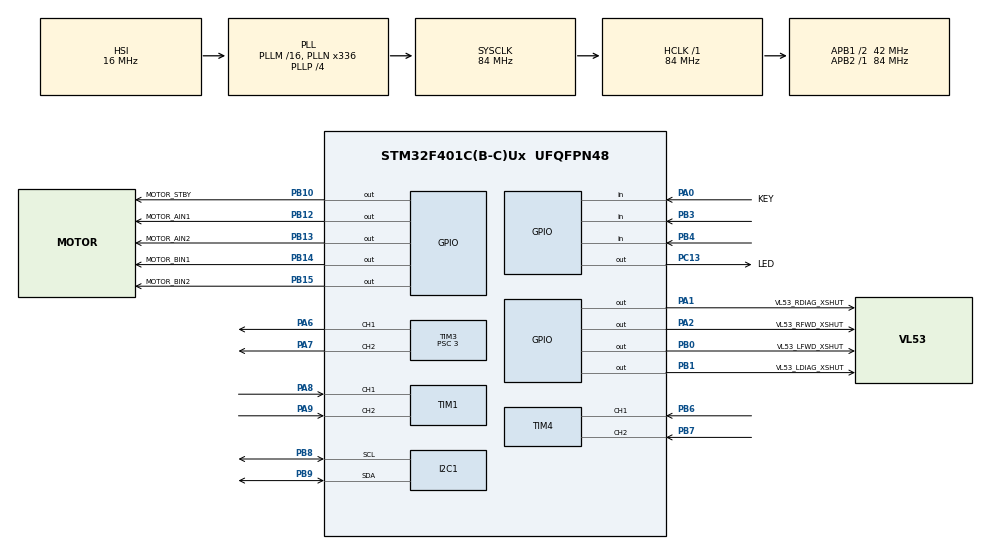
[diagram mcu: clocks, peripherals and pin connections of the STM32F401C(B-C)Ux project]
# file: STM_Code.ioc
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I2C1.I2C_Mode=I2C_Fast
Mcu.Family=STM32F4
Mcu.Name=STM32F401C(B-C)Ux
Mcu.Package=UFQFPN48
NVIC.PriorityGroup=NVIC_PRIORITYGROUP_4
PA0-WKUP.GPIO_Label=KEY
PA0-WKUP.GPIO_PuPd=GPIO_PULLUP
PA0-WKUP.Signal=GPIO_Input
PA1.GPIO_Label=VL53_RDIAG_XSHUT
PA1.GPIO_PuPd=GPIO_NOPULL
PA1.GPIO_Speed=GPIO_SPEED_FREQ_LOW
PA1.Signal=GPIO_Output
PA2.GPIO_Label=VL53_RFWD_XSHUT
PA2.GPIO_PuPd=GPIO_NOPULL
PA2.GPIO_Speed=GPIO_SPEED_FREQ_LOW
PA2.Signal=GPIO_Output
PB0.GPIO_Label=VL53_LFWD_XSHUT
PB0.GPIO_PuPd=GPIO_NOPULL
PB0.GPIO_Speed=GPIO_SPEED_FREQ_LOW
PB0.Signal=GPIO_Output
PB1.GPIO_Label=VL53_LDIAG_XSHUT
PB1.GPIO_PuPd=GPIO_NOPULL
PB1.GPIO_Speed=GPIO_SPEED_FREQ_LOW
PB1.Signal=GPIO_Output
PA13.Mode=Serial_Wire
PA13.Signal=SYS_JTMS-SWDIO
PA14.Mode=Serial_Wire
PA14.Signal=SYS_JTCK-SWCLK
PA6.Signal=S_TIM3_CH1
PA7.Signal=S_TIM3_CH2
PA8.Signal=S_TIM1_CH1
PA9.Signal=S_TIM1_CH2
PB10.GPIO_Label=MOTOR_STBY
PB10.Signal=GPIO_Output
PB12.GPIO_Label=MOTOR_AIN1
PB12.Signal=GPIO_Output
PB13.GPIO_Label=MOTOR_AIN2
PB13.Signal=GPIO_Output
PB14.GPIO_Label=MOTOR_BIN1
PB14.Signal=GPIO_Output
PB15.GPIO_Label=MOTOR_BIN2
PB15.Signal=GPIO_Output
PB3.GPIO_PuPd=GPIO_PULLUP
PB3.Signal=GPIO_Input
PB4.GPIO_PuPd=GPIO_PULLUP
PB4.Signal=GPIO_Input
PB6.Signal=S_TIM4_CH1
PB7.Signal=S_TIM4_CH2
PB8.Mode=I2C
PB8.Signal=I2C1_SCL
PB9.Mode=I2C
PB9.Signal=I2C1_SDA
PC13-ANTI_TAMP.GPIO_Label=LED
PC13-ANTI_TAMP.GPIO_PuPd=GPIO_NOPULL
PC13-ANTI_TAMP.PinState=GPIO_PIN_SET
PC13-ANTI_TAMP.Signal=GPIO_Output
ProjectManager.HeapSize=0x200
ProjectManager.StackSize=0x400
ProjectManager.TargetToolchain=STM32CubeIDE
RCC.48MHZClocksFreq_Value=84000000
RCC.AHBFreq_Value=84000000
RCC.APB1CLKDivider=RCC_HCLK_DIV2
RCC.APB1Freq_Value=42000000
RCC.APB1TimFreq_Value=84000000
RCC.APB2Freq_Value=84000000
RCC.APB2TimFreq_Value=84000000
RCC.CortexFreq_Value=84000000
RCC.HCLKFreq_Value=84000000
RCC.HSE_VALUE=25000000
RCC.HSI_VALUE=16000000
RCC.LSE_VALUE=32768
RCC.PLLN=336
RCC.PLLP=RCC_PLLP_DIV4
RCC.SYSCLKFreq_VALUE=84000000
RCC.SYSCLKSource=RCC_SYSCLKSOURCE_PLLCLK
RCC.VCOOutputFreq_Value=336000000
SH.S_TIM1_CH1.0=TIM1_CH1,Encoder_Interface
SH.S_TIM1_CH2.0=TIM1_CH2,Encoder_Interface
SH.S_TIM3_CH1.0=TIM3_CH1,PWM Generation1 CH1
SH.S_TIM3_CH2.0=TIM3_CH2,PWM Generation2 CH2
SH.S_TIM4_CH1.0=TIM4_CH1,Encoder_Interface
SH.S_TIM4_CH2.0=TIM4_CH2,Encoder_Interface
TIM1.EncoderMode=TIM_ENCODERMODE_TI12
TIM1.IC1Filter=4
TIM1.IC2Filter=4
TIM3.Channel-PWM\ Generation1\ CH1=TIM_CHANNEL_1
TIM3.Channel-PWM\ Generation2\ CH2=TIM_CHANNEL_2
TIM3.AutoReloadPreload=TIM_AUTORELOAD_PRELOAD_DISABLE
TIM3.ClockDivision=TIM_CLOCKDIVISION_DIV1
TIM3.CounterMode=TIM_COUNTERMODE_UP
TIM3.Period=999
TIM3.Prescaler=3
TIM4.EncoderMode=TIM_ENCODERMODE_TI12
TIM4.IC1Filter=4
TIM4.IC2Filter=4
VP_TIM3_VS_ClockSourceINT.Mode=Internal
board=custom

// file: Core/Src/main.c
/* USER CODE BEGIN Header */
/**
  ******************************************************************************
  * @file           : main.c
  * @brief          : Main program body
  ******************************************************************************
  * @attention
  *
  * Copyright (c) 2026 STMicroelectronics.
  * All rights reserved.
  *
  * This software is licensed under terms that can be found in the LICENSE file
  * in the root directory of this software component.
  * If no LICENSE file comes with this software, it is provided AS-IS.
  *
  ******************************************************************************
  */
/* USER CODE END Header */
#include "main.h"
#include "hardware_test.h"
#include "motor.h"
#include "motion.h"
#include "encoder.h"
#include "speed_control.h"
#include "tof_sensors.h"
#include "wall_detection.h"
#include "oled.h"

I2C_HandleTypeDef hi2c1;

TIM_HandleTypeDef htim1;
TIM_HandleTypeDef htim3;
TIM_HandleTypeDef htim4;

void SystemClock_Config(void);
static void MX_GPIO_Init(void);
static void MX_I2C1_Init(void);
static void MX_TIM1_Init(void);
static void MX_TIM3_Init(void);
static void MX_TIM4_Init(void);

int main(void)
{

  /* MCU Configuration--------------------------------------------------------*/

  /* Reset of all peripherals, Initializes the Flash interface and the Systick. */
  HAL_Init();

  /* Configure the system clock */
  SystemClock_Config();

  /* Initialize all configured peripherals */
  MX_GPIO_Init();
  MX_I2C1_Init();
  MX_TIM1_Init();
  MX_TIM3_Init();
  MX_TIM4_Init();
  /* USER CODE BEGIN 2 */

  /* Initialize motor PWM, but keep TB6612 STBY low until motion is requested. */
  motor_init();

  /*
   * Hardware verification mode.
   *
   * CubeMX owns all peripheral initialization above. The diagnostic layer
   * only consumes the initialized GPIO, I2C1, TIM1 and TIM4 peripherals.
   */
  encoder_init();
  speed_control_init();
  motion_init();
  wall_detection_init();
  hardware_test_init();
  if (!tof_sensors_init()) {
    oled_show_message("TOF ERROR", "CHECK WIRING");
    HAL_Delay(1000);
  }

  /* USER CODE END 2 */

  /* Infinite loop */
  /* USER CODE BEGIN WHILE */
  while (1)
  {
    /* Update encoder state exactly once per main-loop iteration. */
    encoder_update();
    tof_sensors_update();
    wall_detection_update();

    /* Motion controller is idle until a motion command is issued. */
    motion_update();
    hardware_test_run();

    /* USER CODE END WHILE */

  }
}

void SystemClock_Config(void)
{
  RCC_OscInitTypeDef RCC_OscInitStruct = {0};
  RCC_ClkInitTypeDef RCC_ClkInitStruct = {0};

  /** Configure the main internal regulator output voltage
  */
  __HAL_RCC_PWR_CLK_ENABLE();
  __HAL_PWR_VOLTAGESCALING_CONFIG(PWR_REGULATOR_VOLTAGE_SCALE2);

  /** Initializes the RCC Oscillators according to the specified parameters
  * in the RCC_OscInitTypeDef structure.
  */
  RCC_OscInitStruct.OscillatorType = RCC_OSCILLATORTYPE_HSI;
  RCC_OscInitStruct.HSIState = RCC_HSI_ON;
  RCC_OscInitStruct.HSICalibrationValue = RCC_HSICALIBRATION_DEFAULT;
  RCC_OscInitStruct.PLL.PLLState = RCC_PLL_ON;
  RCC_OscInitStruct.PLL.PLLSource = RCC_PLLSOURCE_HSI;
  RCC_OscInitStruct.PLL.PLLM = 16;
  RCC_OscInitStruct.PLL.PLLN = 336;
  RCC_OscInitStruct.PLL.PLLP = RCC_PLLP_DIV4;
  RCC_OscInitStruct.PLL.PLLQ = 4;
  if (HAL_RCC_OscConfig(&RCC_OscInitStruct) != HAL_OK)
  {
    Error_Handler();
  }

  /** Initializes the CPU, AHB and APB buses clocks
  */
  RCC_ClkInitStruct.ClockType = RCC_CLOCKTYPE_HCLK|RCC_CLOCKTYPE_SYSCLK
                              |RCC_CLOCKTYPE_PCLK1|RCC_CLOCKTYPE_PCLK2;
  RCC_ClkInitStruct.SYSCLKSource = RCC_SYSCLKSOURCE_PLLCLK;
  RCC_ClkInitStruct.AHBCLKDivider = RCC_SYSCLK_DIV1;
  RCC_ClkInitStruct.APB1CLKDivider = RCC_HCLK_DIV2;
  RCC_ClkInitStruct.APB2CLKDivider = RCC_HCLK_DIV1;

  if (HAL_RCC_ClockConfig(&RCC_ClkInitStruct, FLASH_LATENCY_2) != HAL_OK)
  {
    Error_Handler();
  }
}

static void MX_I2C1_Init(void)
{

  hi2c1.Instance = I2C1;
  hi2c1.Init.ClockSpeed = 400000;
  hi2c1.Init.DutyCycle = I2C_DUTYCYCLE_2;
  hi2c1.Init.OwnAddress1 = 0;
  hi2c1.Init.AddressingMode = I2C_ADDRESSINGMODE_7BIT;
  hi2c1.Init.DualAddressMode = I2C_DUALADDRESS_DISABLE;
  hi2c1.Init.OwnAddress2 = 0;
  hi2c1.Init.GeneralCallMode = I2C_GENERALCALL_DISABLE;
  hi2c1.Init.NoStretchMode = I2C_NOSTRETCH_DISABLE;
  if (HAL_I2C_Init(&hi2c1) != HAL_OK)
  {
    Error_Handler();
  }

}

static void MX_TIM1_Init(void)
{

  TIM_Encoder_InitTypeDef sConfig = {0};
  TIM_MasterConfigTypeDef sMasterConfig = {0};

  htim1.Instance = TIM1;
  htim1.Init.Prescaler = 0;
  htim1.Init.CounterMode = TIM_COUNTERMODE_UP;
  htim1.Init.Period = 65535;
  htim1.Init.ClockDivision = TIM_CLOCKDIVISION_DIV1;
  htim1.Init.RepetitionCounter = 0;
  htim1.Init.AutoReloadPreload = TIM_AUTORELOAD_PRELOAD_DISABLE;
  sConfig.EncoderMode = TIM_ENCODERMODE_TI12;
  sConfig.IC1Polarity = TIM_ICPOLARITY_RISING;
  sConfig.IC1Selection = TIM_ICSELECTION_DIRECTTI;
  sConfig.IC1Prescaler = TIM_ICPSC_DIV1;
  sConfig.IC1Filter = 4;
  sConfig.IC2Polarity = TIM_ICPOLARITY_RISING;
  sConfig.IC2Selection = TIM_ICSELECTION_DIRECTTI;
  sConfig.IC2Prescaler = TIM_ICPSC_DIV1;
  sConfig.IC2Filter = 4;
  if (HAL_TIM_Encoder_Init(&htim1, &sConfig) != HAL_OK)
  {
    Error_Handler();
  }
  sMasterConfig.MasterOutputTrigger = TIM_TRGO_RESET;
  sMasterConfig.MasterSlaveMode = TIM_MASTERSLAVEMODE_DISABLE;
  if (HAL_TIMEx_MasterConfigSynchronization(&htim1, &sMasterConfig) != HAL_OK)
  {
    Error_Handler();
  }

}

static void MX_TIM3_Init(void)
{

  TIM_ClockConfigTypeDef sClockSourceConfig = {0};
  TIM_MasterConfigTypeDef sMasterConfig = {0};
  TIM_OC_InitTypeDef sConfigOC = {0};

  htim3.Instance = TIM3;
  htim3.Init.Prescaler = 3;
  htim3.Init.CounterMode = TIM_COUNTERMODE_UP;
  htim3.Init.Period = 999;
  htim3.Init.ClockDivision = TIM_CLOCKDIVISION_DIV1;
  htim3.Init.AutoReloadPreload = TIM_AUTORELOAD_PRELOAD_DISABLE;
  if (HAL_TIM_Base_Init(&htim3) != HAL_OK)
  {
    Error_Handler();
  }
  sClockSourceConfig.ClockSource = TIM_CLOCKSOURCE_INTERNAL;
  if (HAL_TIM_ConfigClockSource(&htim3, &sClockSourceConfig) != HAL_OK)
  {
    Error_Handler();
  }
  if (HAL_TIM_PWM_Init(&htim3) != HAL_OK)
  {
    Error_Handler();
  }
  sMasterConfig.MasterOutputTrigger = TIM_TRGO_RESET;
  sMasterConfig.MasterSlaveMode = TIM_MASTERSLAVEMODE_DISABLE;
  if (HAL_TIMEx_MasterConfigSynchronization(&htim3, &sMasterConfig) != HAL_OK)
  {
    Error_Handler();
  }
  sConfigOC.OCMode = TIM_OCMODE_PWM1;
  sConfigOC.Pulse = 0;
  sConfigOC.OCPolarity = TIM_OCPOLARITY_HIGH;
  sConfigOC.OCFastMode = TIM_OCFAST_DISABLE;
  if (HAL_TIM_PWM_ConfigChannel(&htim3, &sConfigOC, TIM_CHANNEL_1) != HAL_OK)
  {
    Error_Handler();
  }
  if (HAL_TIM_PWM_ConfigChannel(&htim3, &sConfigOC, TIM_CHANNEL_2) != HAL_OK)
  {
    Error_Handler();
  }
  HAL_TIM_MspPostInit(&htim3);

}

static void MX_TIM4_Init(void)
{

  TIM_Encoder_InitTypeDef sConfig = {0};
  TIM_MasterConfigTypeDef sMasterConfig = {0};

  htim4.Instance = TIM4;
  htim4.Init.Prescaler = 0;
  htim4.Init.CounterMode = TIM_COUNTERMODE_UP;
  htim4.Init.Period = 65535;
  htim4.Init.ClockDivision = TIM_CLOCKDIVISION_DIV1;
  htim4.Init.AutoReloadPreload = TIM_AUTORELOAD_PRELOAD_DISABLE;
  sConfig.EncoderMode = TIM_ENCODERMODE_TI12;
  sConfig.IC1Polarity = TIM_ICPOLARITY_RISING;
  sConfig.IC1Selection = TIM_ICSELECTION_DIRECTTI;
  sConfig.IC1Prescaler = TIM_ICPSC_DIV1;
  sConfig.IC1Filter = 4;
  sConfig.IC2Polarity = TIM_ICPOLARITY_RISING;
  sConfig.IC2Selection = TIM_ICSELECTION_DIRECTTI;
  sConfig.IC2Prescaler = TIM_ICPSC_DIV1;
  sConfig.IC2Filter = 4;
  if (HAL_TIM_Encoder_Init(&htim4, &sConfig) != HAL_OK)
  {
    Error_Handler();
  }
  sMasterConfig.MasterOutputTrigger = TIM_TRGO_RESET;
  sMasterConfig.MasterSlaveMode = TIM_MASTERSLAVEMODE_DISABLE;
  if (HAL_TIMEx_MasterConfigSynchronization(&htim4, &sMasterConfig) != HAL_OK)
  {
    Error_Handler();
  }

}

static void MX_GPIO_Init(void)
{
  GPIO_InitTypeDef GPIO_InitStruct = {0};

  /* GPIO Ports Clock Enable */
  __HAL_RCC_GPIOC_CLK_ENABLE();
  __HAL_RCC_GPIOA_CLK_ENABLE();
  __HAL_RCC_GPIOB_CLK_ENABLE();

  /*Configure GPIO pin Output Level */
  HAL_GPIO_WritePin(LED_GPIO_Port, LED_Pin, GPIO_PIN_SET);

  /*Configure GPIO pin Output Level */
  HAL_GPIO_WritePin(GPIOB, MOTOR_STBY_Pin|MOTOR_AIN1_Pin|MOTOR_AIN2_Pin|MOTOR_BIN1_Pin
                          |MOTOR_BIN2_Pin|VL53_LFWD_XSHUT_Pin|VL53_LDIAG_XSHUT_Pin, GPIO_PIN_RESET);
  HAL_GPIO_WritePin(GPIOA, VL53_RDIAG_XSHUT_Pin|VL53_RFWD_XSHUT_Pin, GPIO_PIN_RESET);

  /*Configure VL53L0X XSHUT pins low before sensor initialization */
  GPIO_InitStruct.Pin = VL53_LFWD_XSHUT_Pin|VL53_LDIAG_XSHUT_Pin;
  GPIO_InitStruct.Mode = GPIO_MODE_OUTPUT_PP;
  GPIO_InitStruct.Pull = GPIO_NOPULL;
  GPIO_InitStruct.Speed = GPIO_SPEED_FREQ_LOW;
  HAL_GPIO_Init(GPIOB, &GPIO_InitStruct);

  GPIO_InitStruct.Pin = VL53_RDIAG_XSHUT_Pin|VL53_RFWD_XSHUT_Pin;
  HAL_GPIO_Init(GPIOA, &GPIO_InitStruct);

  /*Configure GPIO pin : LED_Pin */
  GPIO_InitStruct.Pin = LED_Pin;
  GPIO_InitStruct.Mode = GPIO_MODE_OUTPUT_PP;
  GPIO_InitStruct.Pull = GPIO_NOPULL;
  GPIO_InitStruct.Speed = GPIO_SPEED_FREQ_LOW;
  HAL_GPIO_Init(LED_GPIO_Port, &GPIO_InitStruct);

  /*Configure GPIO pin : KEY_Pin */
  GPIO_InitStruct.Pin = KEY_Pin;
  GPIO_InitStruct.Mode = GPIO_MODE_INPUT;
  GPIO_InitStruct.Pull = GPIO_PULLUP;
  HAL_GPIO_Init(KEY_GPIO_Port, &GPIO_InitStruct);

  /*Configure GPIO pins : MOTOR_STBY_Pin MOTOR_AIN1_Pin MOTOR_AIN2_Pin MOTOR_BIN1_Pin
                           MOTOR_BIN2_Pin */
  GPIO_InitStruct.Pin = MOTOR_STBY_Pin|MOTOR_AIN1_Pin|MOTOR_AIN2_Pin|MOTOR_BIN1_Pin
                          |MOTOR_BIN2_Pin;
  GPIO_InitStruct.Mode = GPIO_MODE_OUTPUT_PP;
  GPIO_InitStruct.Pull = GPIO_NOPULL;
  GPIO_InitStruct.Speed = GPIO_SPEED_FREQ_LOW;
  HAL_GPIO_Init(GPIOB, &GPIO_InitStruct);

  /*Configure GPIO pins : PB3 PB4 */
  GPIO_InitStruct.Pin = GPIO_PIN_3|GPIO_PIN_4;
  GPIO_InitStruct.Mode = GPIO_MODE_INPUT;
  GPIO_InitStruct.Pull = GPIO_PULLUP;
  HAL_GPIO_Init(GPIOB, &GPIO_InitStruct);

}

void Error_Handler(void)
{
  __disable_irq();
  while (1)
  {
  }
}
